VERSION ""

NS_ :

BS_:

BU_: XXX

BO_ 2 A_M_1: 8 XXX
 SG_ Counter : 0|4@1+ (1,0) [0|15] "" XXX
 SG_ Master_Counter : 32|24@1+ (1,0) [0|16777215] "" XXX

BO_ 4 M_2: 8 XXX
 SG_ Counter : 0|4@1+ (1,0) [0|15] "" XXX
 SG_ Master_Counter : 32|24@1+ (1,0) [0|16777215] "" XXX

BO_ 1037 A_40D: 8 XXX
 SG_ TEST_SIG : 36|12@1+ (1,0) [0|63] "" XXX

BO_ 1043 A_413: 8 XXX
 SG_ NEW_SIGNAL_1 : 16|16@1+ (1,0) [0|65535] "" XXX
 SG_  : 0|12@1+ (1,-2092.00) [0|7] "" XXX

BO_ 1035 A_40B: 8 XXX
 SG_ NEW_SIGNAL_1 : 0|7@1+ (1,0) [0|65535] "" XXX

BO_ 18 A_M_3: 8 XXX
 SG_ Master_Counter : 32|24@1+ (1,0) [0|16777215] "" XXX
 SG_ Counter : 16|4@1+ (1,0) [0|63] "" XXX

BO_ 20 M_4: 8 XXX
 SG_ Counter : 16|4@1+ (1,0) [0|15] "" XXX
 SG_ Master_Counter : 39|24@0+ (1,0) [0|16777215] "" XXX

BO_ 769 301: 8 XXX
 SG_ Counter : 0|4@1+ (1,0) [0|7] "" XXX

BO_ 1010 A_3F2: 8 XXX
 SG_ Counter : 0|4@1+ (1,0) [0|15] "" XXX
 SG_ Master_Counter : 32|24@1+ (1,0) [0|16777215] "" XXX

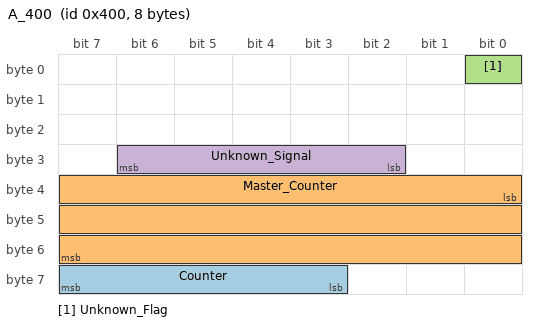
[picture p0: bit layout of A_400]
BO_ 1024 A_400: 8 XXX
 SG_ Counter : 63|5@0+ (1,0) [0|31] "" XXX
 SG_ Master_Counter : 32|24@1+ (1,0) [0|65535] "" XXX
 SG_ Unknown_Flag : 0|1@1+ (1,0) [0|31] "" XXX
 SG_ Unknown_Signal : 30|5@0+ (1,0) [0|31] "" XXX

BO_ 992 A_3E0: 8 XXX

BO_ 993 A_3E1: 8 XXX

BO_ 1025 A_401: 8 XXX

BO_ 1044 A_414: 8 XXX

BO_ 1042 A_412: 8 XXX

BO_ 1041 A_411: 8 XXX

BO_ 1026 A_402: 8 XXX

BO_ 1027 A_403: 8 XXX

BO_ 1028 A_404: 8 XXX

BO_ 1029 A_405: 8 XXX

BO_ 1030 A_406: 8 XXX

BO_ 1031 A_407: 8 XXX

BO_ 1032 A_408: 8 XXX

BO_ 1033 A_409: 8 XXX

BO_ 1034 A_40A: 8 XXX

BO_ 1036 A_40C: 8 XXX

BO_ 1104 A_450: 8 XXX

BO_ 1136 A_470: 8 XXX
 SG_ NEW_SIGNAL_1 : 24|16@1+ (1,0) [0|32767] "" XXX

BO_ 1137 A_471: 8 XXX

BO_ 1140 A_474: 8 XXX

BO_ 1142 A_476: 8 XXX

BO_ 1143 A_477: 8 XXX

BO_ 1200 A_4B0: 8 XXX

BO_ 1600 A_640: 8 XXX

BO_ 1601 A_641: 8 XXX

BO_ 1602 A_642: 8 XXX

BO_ 1618 A_652: 8 XXX

BO_ 1633 A_661: 8 XXX

BO_ 1635 A_663: 8 XXX

BO_ 1792 A_700: 8 XXX

BO_ 2032 A_7F0: 8 XXX

BO_ 2033 A_7F1: 8 XXX

BO_ 2036 A_7F4: 8 XXX

BO_ 1038 A_40E: 8 XXX
 SG_ NEW_SIGNAL_1 : 0|12@1+ (1,0) [0|63] "" XXX

BO_ 1039 A_40F: 8 XXX

BO_ 1040 A_410: 8 XXX

BO_ 1073 NEW_MSG_1: 8 XXX
 SG_ NEW_SIGNAL_1 : 16|8@1+ (1,0) [0|65535] "" XXX

BO_ 1074 NEW_MSG_2: 8 XXX
 SG_ NEW_SIGNAL_2 : 56|8@1+ (1,0) [0|7] "" XXX
 SG_ NEW_SIGNAL_1 : 32|13@1+ (1,0) [0|63] "" XXX

BO_ 1280 NEW_MSG_3: 8 XXX
 SG_ NEW_SIGNAL_1 : 20|5@0+ (1,0) [0|31] "" XXX

BO_ 1088 NEW_MSG_4: 8 XXX
 SG_ NEW_SIGNAL_1 : 0|12@1+ (1,0) [0|127] "" XXX
